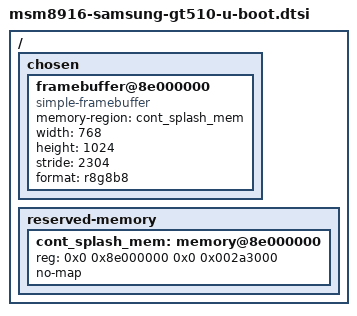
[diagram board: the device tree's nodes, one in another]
// SPDX-License-Identifier: GPL-2.0

#include <config.h>
#include <dt-bindings/arm/qcom,ids.h>

/ {
	chosen {
		framebuffer@8e000000 {
			compatible = "simple-framebuffer";
			memory-region = <&cont_splash_mem>;
			width = <768>;
			height = <1024>;
			stride = <2304>;
			format = "r8g8b8";
		};
	};

	reserved-memory {
		#address-cells = <2>;
		#size-cells = <2>;
		ranges;

		cont_splash_mem: memory@8e000000 {
			reg = <0x0 0x8e000000 0x0 0x002a3000>;
			no-map;
		};
	};
};
